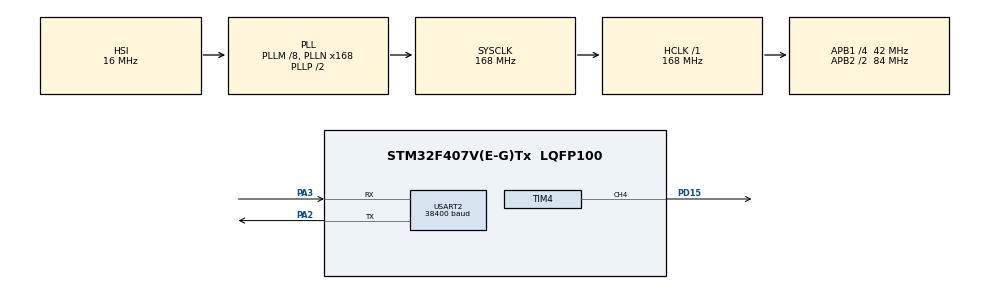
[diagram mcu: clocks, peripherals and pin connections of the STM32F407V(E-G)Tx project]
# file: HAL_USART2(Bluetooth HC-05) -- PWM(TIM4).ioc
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Mcu.Family=STM32F4
Mcu.Name=STM32F407V(E-G)Tx
Mcu.Package=LQFP100
NVIC.PriorityGroup=NVIC_PRIORITYGROUP_4
NVIC.USART2_IRQn=true\:0\:0\:false\:false\:true\:true\:true
PA2.Mode=Asynchronous
PA2.Signal=USART2_TX
PA3.Mode=Asynchronous
PA3.Signal=USART2_RX
PD15.Signal=S_TIM4_CH4
PH0-OSC_IN.Mode=HSE-External-Oscillator
PH0-OSC_IN.Signal=RCC_OSC_IN
PH1-OSC_OUT.Mode=HSE-External-Oscillator
PH1-OSC_OUT.Signal=RCC_OSC_OUT
ProjectManager.HeapSize=0x200
ProjectManager.StackSize=0x400
ProjectManager.TargetToolchain=STM32CubeIDE
RCC.48MHZClocksFreq_Value=84000000
RCC.AHBFreq_Value=168000000
RCC.APB1CLKDivider=RCC_HCLK_DIV4
RCC.APB1Freq_Value=42000000
RCC.APB1TimFreq_Value=84000000
RCC.APB2CLKDivider=RCC_HCLK_DIV2
RCC.APB2Freq_Value=84000000
RCC.APB2TimFreq_Value=168000000
RCC.CortexFreq_Value=168000000
RCC.HCLKFreq_Value=168000000
RCC.HSE_VALUE=8000000
RCC.HSI_VALUE=16000000
RCC.LSE_VALUE=32768
RCC.PLLM=8
RCC.PLLN=168
RCC.SYSCLKFreq_VALUE=168000000
RCC.SYSCLKSource=RCC_SYSCLKSOURCE_PLLCLK
RCC.VCOOutputFreq_Value=336000000
SH.S_TIM4_CH4.0=TIM4_CH4,PWM Generation4 CH4
TIM4.Channel-PWM\ Generation4\ CH4=TIM_CHANNEL_4
TIM4.Period=100
TIM4.Prescaler=84-1
USART2.BaudRate=38400
USART2.VirtualMode=VM_ASYNC
VP_TIM4_VS_ClockSourceINT.Mode=Internal
board=custom

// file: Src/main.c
/* USER CODE BEGIN Header */
/**
  ******************************************************************************
  * @file           : main.c
  * @brief          : Main program body
  ******************************************************************************
  * @attention
  *
  * <h2><center>&copy; Copyright (c) 2020 STMicroelectronics.
  * All rights reserved.</center></h2>
  *
  * This software component is licensed by ST under BSD 3-Clause license,
  * the "License"; You may not use this file except in compliance with the
  * License. You may obtain a copy of the License at:
  *                        opensource.org/licenses/BSD-3-Clause
  *
  ******************************************************************************
  */
/* USER CODE END Header */

#include "main.h"

/* USER CODE BEGIN Includes */

extern uint8_t Rx_Data[5];
extern uint8_t Rx_Byte[1];
extern uint8_t Rx_DataCnt;
extern uint8_t Data;

/* USER CODE END Includes */

TIM_HandleTypeDef htim4;

UART_HandleTypeDef huart2;

void SystemClock_Config(void);
static void MX_GPIO_Init(void);
static void MX_TIM4_Init(void);
static void MX_USART2_UART_Init(void);

int main(void)
{

  /* MCU Configuration--------------------------------------------------------*/

  /* Reset of all peripherals, Initializes the Flash interface and the Systick. */
  HAL_Init();

  /* Configure the system clock */
  SystemClock_Config();

  /* Initialize all configured peripherals */
  MX_GPIO_Init();
  MX_TIM4_Init();
  MX_USART2_UART_Init();
  /* USER CODE BEGIN 2 */

  __HAL_UART_ENABLE_IT(&huart2,UART_IT_RXNE);

  HAL_UART_Transmit(&huart2,"sa",2,100);

  HAL_TIM_PWM_Start(&htim4,TIM_CHANNEL_4);

  /* USER CODE END 2 */

  /* Infinite loop */
  while (1)
  {

  }
}

void SystemClock_Config(void)
{
  RCC_OscInitTypeDef RCC_OscInitStruct = {0};
  RCC_ClkInitTypeDef RCC_ClkInitStruct = {0};

  /** Configure the main internal regulator output voltage
  */
  __HAL_RCC_PWR_CLK_ENABLE();
  __HAL_PWR_VOLTAGESCALING_CONFIG(PWR_REGULATOR_VOLTAGE_SCALE1);
  /** Initializes the CPU, AHB and APB busses clocks
  */
  RCC_OscInitStruct.OscillatorType = RCC_OSCILLATORTYPE_HSI;
  RCC_OscInitStruct.HSIState = RCC_HSI_ON;
  RCC_OscInitStruct.HSICalibrationValue = RCC_HSICALIBRATION_DEFAULT;
  RCC_OscInitStruct.PLL.PLLState = RCC_PLL_ON;
  RCC_OscInitStruct.PLL.PLLSource = RCC_PLLSOURCE_HSI;
  RCC_OscInitStruct.PLL.PLLM = 8;
  RCC_OscInitStruct.PLL.PLLN = 168;
  RCC_OscInitStruct.PLL.PLLP = RCC_PLLP_DIV2;
  RCC_OscInitStruct.PLL.PLLQ = 4;
  if (HAL_RCC_OscConfig(&RCC_OscInitStruct) != HAL_OK)
  {
    Error_Handler();
  }
  /** Initializes the CPU, AHB and APB busses clocks
  */
  RCC_ClkInitStruct.ClockType = RCC_CLOCKTYPE_HCLK|RCC_CLOCKTYPE_SYSCLK
                              |RCC_CLOCKTYPE_PCLK1|RCC_CLOCKTYPE_PCLK2;
  RCC_ClkInitStruct.SYSCLKSource = RCC_SYSCLKSOURCE_PLLCLK;
  RCC_ClkInitStruct.AHBCLKDivider = RCC_SYSCLK_DIV1;
  RCC_ClkInitStruct.APB1CLKDivider = RCC_HCLK_DIV4;
  RCC_ClkInitStruct.APB2CLKDivider = RCC_HCLK_DIV2;

  if (HAL_RCC_ClockConfig(&RCC_ClkInitStruct, FLASH_LATENCY_5) != HAL_OK)
  {
    Error_Handler();
  }
}

static void MX_TIM4_Init(void)
{

  TIM_ClockConfigTypeDef sClockSourceConfig = {0};
  TIM_MasterConfigTypeDef sMasterConfig = {0};
  TIM_OC_InitTypeDef sConfigOC = {0};

  htim4.Instance = TIM4;
  htim4.Init.Prescaler = 84-1;
  htim4.Init.CounterMode = TIM_COUNTERMODE_UP;
  htim4.Init.Period = 1000;
  htim4.Init.ClockDivision = TIM_CLOCKDIVISION_DIV1;
  htim4.Init.AutoReloadPreload = TIM_AUTORELOAD_PRELOAD_DISABLE;
  if (HAL_TIM_Base_Init(&htim4) != HAL_OK)
  {
    Error_Handler();
  }
  sClockSourceConfig.ClockSource = TIM_CLOCKSOURCE_INTERNAL;
  if (HAL_TIM_ConfigClockSource(&htim4, &sClockSourceConfig) != HAL_OK)
  {
    Error_Handler();
  }
  if (HAL_TIM_PWM_Init(&htim4) != HAL_OK)
  {
    Error_Handler();
  }
  sMasterConfig.MasterOutputTrigger = TIM_TRGO_RESET;
  sMasterConfig.MasterSlaveMode = TIM_MASTERSLAVEMODE_DISABLE;
  if (HAL_TIMEx_MasterConfigSynchronization(&htim4, &sMasterConfig) != HAL_OK)
  {
    Error_Handler();
  }
  sConfigOC.OCMode = TIM_OCMODE_PWM1;
  sConfigOC.Pulse = 0;
  sConfigOC.OCPolarity = TIM_OCPOLARITY_HIGH;
  sConfigOC.OCFastMode = TIM_OCFAST_DISABLE;
  if (HAL_TIM_PWM_ConfigChannel(&htim4, &sConfigOC, TIM_CHANNEL_4) != HAL_OK)
  {
    Error_Handler();
  }
  HAL_TIM_MspPostInit(&htim4);

}

static void MX_USART2_UART_Init(void)
{

  huart2.Instance = USART2;
  huart2.Init.BaudRate = 38400;
  huart2.Init.WordLength = UART_WORDLENGTH_8B;
  huart2.Init.StopBits = UART_STOPBITS_1;
  huart2.Init.Parity = UART_PARITY_NONE;
  huart2.Init.Mode = UART_MODE_TX_RX;
  huart2.Init.HwFlowCtl = UART_HWCONTROL_NONE;
  huart2.Init.OverSampling = UART_OVERSAMPLING_16;
  if (HAL_UART_Init(&huart2) != HAL_OK)
  {
    Error_Handler();
  }

}

static void MX_GPIO_Init(void)
{

  /* GPIO Ports Clock Enable */
  __HAL_RCC_GPIOH_CLK_ENABLE();
  __HAL_RCC_GPIOA_CLK_ENABLE();
  __HAL_RCC_GPIOD_CLK_ENABLE();

}

void Error_Handler(void)
{
}

/************************ (C) COPYRIGHT STMicroelectronics *****END OF FILE****/
